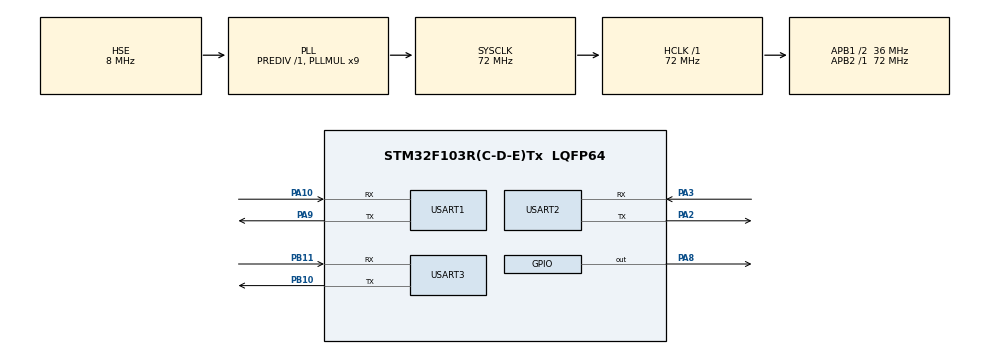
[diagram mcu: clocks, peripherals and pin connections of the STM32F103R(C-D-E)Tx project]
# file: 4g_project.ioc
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FREERTOS.Tasks01=defaultTask,24,128,StartDefaultTask,Default,NULL,Dynamic,NULL,NULL
Mcu.Family=STM32F1
Mcu.Name=STM32F103R(C-D-E)Tx
Mcu.Package=LQFP64
NVIC.PriorityGroup=NVIC_PRIORITYGROUP_4
NVIC.TIM6_IRQn=true\:15\:0\:false\:false\:true\:false\:false\:true
NVIC.TimeBase=TIM6_IRQn
NVIC.TimeBaseIP=TIM6
PA10.Mode=Asynchronous
PA10.Signal=USART1_RX
PA13.Mode=Serial_Wire
PA13.Signal=SYS_JTMS-SWDIO
PA14.Mode=Serial_Wire
PA14.Signal=SYS_JTCK-SWCLK
PA2.Mode=Asynchronous
PA2.Signal=USART2_TX
PA3.Mode=Asynchronous
PA3.Signal=USART2_RX
PA8.GPIO_ModeDefaultOutputPP=GPIO_MODE_OUTPUT_PP
PA8.Signal=GPIO_Output
PA9.Mode=Asynchronous
PA9.Signal=USART1_TX
PB10.Mode=Asynchronous
PB10.Signal=USART3_TX
PB11.Mode=Asynchronous
PB11.Signal=USART3_RX
PD0-OSC_IN.Mode=HSE-External-Oscillator
PD0-OSC_IN.Signal=RCC_OSC_IN
PD1-OSC_OUT.Mode=HSE-External-Oscillator
PD1-OSC_OUT.Signal=RCC_OSC_OUT
ProjectManager.HeapSize=0x200
ProjectManager.StackSize=0x400
ProjectManager.TargetToolchain=MDK-ARM V5.32
RCC.AHBFreq_Value=72000000
RCC.APB1CLKDivider=RCC_HCLK_DIV2
RCC.APB1Freq_Value=36000000
RCC.APB1TimFreq_Value=72000000
RCC.APB2Freq_Value=72000000
RCC.APB2TimFreq_Value=72000000
RCC.HCLKFreq_Value=72000000
RCC.PLLMUL=RCC_PLL_MUL9
RCC.PLLSourceVirtual=RCC_PLLSOURCE_HSE
RCC.SYSCLKFreq_VALUE=72000000
RCC.SYSCLKSource=RCC_SYSCLKSOURCE_PLLCLK
RCC.USBFreq_Value=72000000
USART1.VirtualMode=VM_ASYNC
USART2.VirtualMode=VM_ASYNC
USART3.VirtualMode=VM_ASYNC
VP_FREERTOS_VS_CMSIS_V2.Mode=CMSIS_V2
VP_SYS_VS_tim6.Mode=TIM6
board=custom

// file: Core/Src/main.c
/* USER CODE BEGIN Header */
/**
  ******************************************************************************
  * @file           : main.c
  * @brief          : Main program body
  ******************************************************************************
  * @attention
  *
  * <h2><center>&copy; Copyright (c) 2026 STMicroelectronics.
  * All rights reserved.</center></h2>
  *
  * This software component is licensed by ST under Ultimate Liberty license
  * SLA0044, the "License"; You may not use this file except in compliance with
  * the License. You may obtain a copy of the License at:
  *                             www.st.com/SLA0044
  *
  ******************************************************************************
  */
/* USER CODE END Header */
#include "main.h"
#include "cmsis_os.h"
#include "usart.h"
#include "gpio.h"

/* USER CODE BEGIN Includes */
#include "app/app_init.h"
#include "bsp/uart/uart_driver.h"
#include "bsp/rs485/rs485.h"
#include "FreeRTOS.h"
#include "task.h"
/* USER CODE END Includes */

void SystemClock_Config(void);
void MX_FREERTOS_Init(void);

int main(void)
{

  /* MCU Configuration--------------------------------------------------------*/

  /* Reset of all peripherals, Initializes the Flash interface and the Systick. */
  HAL_Init();

  /* Configure the system clock */
  SystemClock_Config();

  /* Initialize all configured peripherals */
  MX_GPIO_Init();
  MX_USART1_UART_Init();
  MX_USART2_UART_Init();
  MX_USART3_UART_Init();
  /* USER CODE BEGIN 2 */
	uart_init();
	rs485_init();

	/*
	 * app_init：创建队列/事件组/互斥量、模组上电配置、app_tasks_init 创建业务任务
	 * 均在 osKernelStart 之前完成（静态创建阶段，调度器尚未运行）
	 */
	app_init();
  /* USER CODE END 2 */

  /* Init scheduler */
  osKernelInitialize();  /* CMSIS-RTOS2：初始化内核，尚未运行任务 */
  MX_FREERTOS_Init();    /* Cube 生成：创建 defaultTask（osThreadNew） */
  osKernelStart();       /* 启动调度器；此后仅任务/中断上下文执行，main 不应再跑业务逻辑 */

  /* We should never get here as control is now taken by the scheduler */
  /* Infinite loop */
  while (1)
  {

  }
}

void SystemClock_Config(void)
{
  RCC_OscInitTypeDef RCC_OscInitStruct = {0};
  RCC_ClkInitTypeDef RCC_ClkInitStruct = {0};

  /** Initializes the RCC Oscillators according to the specified parameters
  * in the RCC_OscInitTypeDef structure.
  */
  RCC_OscInitStruct.OscillatorType = RCC_OSCILLATORTYPE_HSE;
  RCC_OscInitStruct.HSEState = RCC_HSE_ON;
  RCC_OscInitStruct.HSEPredivValue = RCC_HSE_PREDIV_DIV1;
  RCC_OscInitStruct.HSIState = RCC_HSI_ON;
  RCC_OscInitStruct.PLL.PLLState = RCC_PLL_ON;
  RCC_OscInitStruct.PLL.PLLSource = RCC_PLLSOURCE_HSE;
  RCC_OscInitStruct.PLL.PLLMUL = RCC_PLL_MUL9;
  if (HAL_RCC_OscConfig(&RCC_OscInitStruct) != HAL_OK)
  {
    Error_Handler();
  }
  /** Initializes the CPU, AHB and APB buses clocks
  */
  RCC_ClkInitStruct.ClockType = RCC_CLOCKTYPE_HCLK|RCC_CLOCKTYPE_SYSCLK
                              |RCC_CLOCKTYPE_PCLK1|RCC_CLOCKTYPE_PCLK2;
  RCC_ClkInitStruct.SYSCLKSource = RCC_SYSCLKSOURCE_PLLCLK;
  RCC_ClkInitStruct.AHBCLKDivider = RCC_SYSCLK_DIV1;
  RCC_ClkInitStruct.APB1CLKDivider = RCC_HCLK_DIV2;
  RCC_ClkInitStruct.APB2CLKDivider = RCC_HCLK_DIV1;

  if (HAL_RCC_ClockConfig(&RCC_ClkInitStruct, FLASH_LATENCY_2) != HAL_OK)
  {
    Error_Handler();
  }
}

void HAL_TIM_PeriodElapsedCallback(TIM_HandleTypeDef *htim)
{
  if (htim->Instance == TIM6) {
    HAL_IncTick();
  }
}

void Error_Handler(void)
{
  __disable_irq();
  while (1)
  {
  }
}

/************************ (C) COPYRIGHT STMicroelectronics *****END OF FILE****/

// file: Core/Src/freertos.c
/* USER CODE BEGIN Header */
/**
  ******************************************************************************
  * File Name          : freertos.c
  * Description        : Code for freertos applications
  ******************************************************************************
  * @attention
  *
  * <h2><center>&copy; Copyright (c) 2026 STMicroelectronics.
  * All rights reserved.</center></h2>
  *
  * This software component is licensed by ST under Ultimate Liberty license
  * SLA0044, the "License"; You may not use this file except in compliance with
  * the License. You may obtain a copy of the License at:
  *                             www.st.com/SLA0044
  *
  ******************************************************************************
  */
/* USER CODE END Header */

#include "FreeRTOS.h"
#include "task.h"
#include "main.h"
#include "cmsis_os.h"

/* USER CODE BEGIN Variables */
/*
 * CubeMX 默认任务：与 Code/app 下原生 xTaskCreate 的业务任务并存。
 * 业务逻辑在 app_tasks.c；本任务仅占位并 osDelay，避免占用过高优先级。
 */
/* USER CODE END Variables */
/* Definitions for defaultTask */
osThreadId_t defaultTaskHandle;
const osThreadAttr_t defaultTask_attributes = {
  .name = "defaultTask",
  .stack_size = 128 * 4,
  .priority = (osPriority_t) osPriorityNormal,
};

void StartDefaultTask(void *argument);

void MX_FREERTOS_Init(void); /* (MISRA C 2004 rule 8.1) */

void MX_FREERTOS_Init(void) {
  /* USER CODE BEGIN Init */
  /* 应用侧队列/任务已在 app_init() 中用 FreeRTOS 原生 API 创建，此处无需重复 */
  /* USER CODE END Init */

  /* USER CODE BEGIN RTOS_MUTEX */
  /* 应用互斥量 g_uart_mutex 见 uart_sync_init() */
  /* USER CODE END RTOS_MUTEX */

  /* USER CODE BEGIN RTOS_SEMAPHORES */
  /* g_monitor_wakeup 等见 app_tasks_init() */
  /* USER CODE END RTOS_SEMAPHORES */

  /* USER CODE BEGIN RTOS_TIMERS */
  /* monitor_timer / switch_lock_timer 见 app_tasks_init() */
  /* USER CODE END RTOS_TIMERS */

  /* USER CODE BEGIN RTOS_QUEUES */
  /* g_queue_* / g_queue_set_forward 见 app_init() */
  /* USER CODE END RTOS_QUEUES */

  /* Create the thread(s) */
  /* creation of defaultTask */
  defaultTaskHandle = osThreadNew(StartDefaultTask, NULL, &defaultTask_attributes);

  /* USER CODE BEGIN RTOS_THREADS */
  /* 业务任务：task_rx / forward / decision / monitor / sim_switch -> app_tasks_init() */
  /* USER CODE END RTOS_THREADS */

  /* USER CODE BEGIN RTOS_EVENTS */
  /* g_app_event_group -> app_init() */
  /* USER CODE END RTOS_EVENTS */

}

void StartDefaultTask(void *argument)
{
  /* USER CODE BEGIN StartDefaultTask */
  (void)argument;
  /* osDelay(1) = 阻塞 1 个 tick（本工程 configTICK_RATE_HZ=1000 即约 1ms），主动让出 CPU */
  for (;;)
  {
    osDelay(1);
  }
  /* USER CODE END StartDefaultTask */
}

/************************ (C) COPYRIGHT STMicroelectronics *****END OF FILE****/
